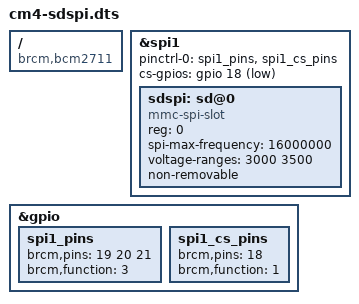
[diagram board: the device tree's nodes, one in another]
/*
 * Device Tree overlay: enable a uSD card socket wired to SPI1 on the CM4
 * daughtercard (see audioCapture/StandaloneDataCollection.md "Installation" ->
 * "Enable the micro-SD on the SPI Bus").
 *
 * Pinout:
 *   CS:   GPIO18, SPI1_CE0_N (GPIO-controlled, not hardware CE — mmc_spi
 *         needs direct control over CS assertion timing)
 *   MISO: GPIO19, SPI1_MISO
 *   MOSI: GPIO20, SPI1_MOSI
 *   SCLK: GPIO21, SPI1_SCLK
 *
 * fragment@1 mux's GPIO19-21 to ALT4 (SPI1) and GPIO18 to plain GPIO
 * output — required because the base device tree does not predefine SPI1
 * pin muxing (those pins are shared with UART3/4/5, PCM, I2S, etc.), so
 * fragment@0's `status = "okay"` alone has no electrical path to the pins
 * without this.
 *
 * Compile and install:
 *   sudo apt install -y device-tree-compiler
 *   dtc -@ -I dts -O dtb -o cm4-sdspi.dtbo cm4-sdspi.dts
 *   sudo install -m 0644 cm4-sdspi.dtbo /boot/firmware/overlays/cm4-sdspi.dtbo
 * Enable by adding to /boot/firmware/config.txt (only this line — no
 * dtparam=spi=on, and no stock spi1-*cs overlay, which would create a
 * competing /dev/spidev1.0 node claiming the same CE0 line):
 *   dtoverlay=cm4-sdspi
 *
 * Verify after reboot:
 *   ls -l /dev/spidev*          # should show nothing for spi1
 *   dmesg | grep -Ei 'spi|mmc'  # look for mmc_spi binding to spi1.0
 *   ls /dev/mmcblk*             # the card, once mmc_spi has claimed it
 *
 * `freq` is exposed as a live-overridable parameter (see __overrides__
 * below) specifically to make sweeping SPI clock speeds fast: this can be
 * removed/reapplied at runtime via configfs with no recompile and no
 * reboot, e.g. to find a given card's max sustainable speed:
 *   sudo dtoverlay -r cm4-sdspi
 *   sudo dtoverlay cm4-sdspi freq=4000000
 *   dmesg | tail -20; ls /dev/mmcblk*
 *   # repeat with different freq= values — "no support for card's volts"
 *   # or a missing /dev/mmcblkN means that speed corrupted the SD init
 *   # handshake; step back down to the last value that worked cleanly.
 * Once a value is confirmed, either set it permanently in
 * /boot/firmware/config.txt (dtoverlay=cm4-sdspi,freq=<value>, which then
 * survives reboots without needing to touch this file) or update the
 * default below to match.
 */

/dts-v1/;
/plugin/;

/ {
    compatible = "brcm,bcm2711";

    fragment@0 {
        target = <&spi1>;
        __overlay__ {
            status = "okay";

            pinctrl-names = "default";
            pinctrl-0 = <&spi1_pins &spi1_cs_pins>;

            /*
             * Use GPIO-controlled CS, active low.
             * GPIO18 is physically connected to the socket CS/DAT3 pin.
             */
            cs-gpios = <&gpio 18 1>;

            #address-cells = <1>;
            #size-cells = <0>;

            sdspi: sd@0 {
                compatible = "mmc-spi-slot";
                reg = <0>;
                spi-max-frequency = <16000000>; /* swept 400kHz-24MHz on hardware (see
                                                    __overrides__ below); 24MHz enumerated
                                                    cleanly and passed a 200MB write+
                                                    read-back sha256 integrity check, but
                                                    16MHz was chosen instead of the tested
                                                    ceiling to leave real margin for
                                                    temperature/voltage/connector-wear
                                                    drift over months of unattended field
                                                    deployment — not just whatever barely
                                                    passed once on the bench. (A *different*
                                                    card previously failed even 12MHz with
                                                    "no support for card's volts" — that was
                                                    a card-specific SPI-mode compatibility
                                                    limitation, not a wiring/frequency
                                                    ceiling; see StandaloneDataCollection.md
                                                    for the full sweep methodology.) */
                voltage-ranges = <3000 3500>;
                non-removable;
                status = "okay";
            };
        };
    };

    fragment@1 {
        target = <&gpio>;
        __overlay__ {
            spi1_pins: spi1_pins {
                brcm,pins = <19 20 21>;
                brcm,function = <3>;   /* ALT4 = SPI1 MISO/MOSI/SCLK */
            };
            spi1_cs_pins: spi1_cs_pins {
                brcm,pins = <18>;
                brcm,function = <1>;   /* output — driven manually as CS */
            };
        };
    };

    __overrides__ {
        freq = <&sdspi>,"spi-max-frequency:0";
    };
};
